# AT90CAN128 device description
Architecture: AVR8; Family: megaAVR
Registers are 8-bit, access not given, no defined reset value unless marked. A register's access mark holds for its fields unless they carry their own. Offsets are from the block's base; [hi:lo] are bit positions; {n}, {i} and the like mark numbered series.

## TC3 (TC16 module) — Timer/Counter, 16-bit
Instances: TC3 0x00
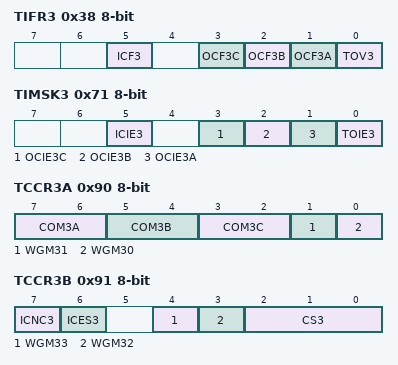
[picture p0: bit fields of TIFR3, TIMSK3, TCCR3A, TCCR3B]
0x38 TIFR3 — Timer/Counter Interrupt Flag register
  [5] ICF3 — Input Capture Flag 3
  [3] OCF3C — Output Compare Flag 3C
  [2] OCF3B — Output Compare Flag 3B
  [1] OCF3A — Output Compare Flag 3A
  [0] TOV3 — Timer/Counter3 Overflow Flag
0x71 TIMSK3 — Timer/Counter Interrupt Mask Register
  [5] ICIE3 — Timer/Counter3 Input Capture Interrupt Enable
  [3] OCIE3C — Timer/Counter3 Output CompareC Match Interrupt Enable
  [2] OCIE3B — Timer/Counter3 Output CompareB Match Interrupt Enable
  [1] OCIE3A — Timer/Counter3 Output CompareA Match Interrupt Enable
  [0] TOIE3 — Timer/Counter3 Overflow Interrupt Enable
0x90 TCCR3A — Timer/Counter3 Control Register A
  [7:6] COM3A — Compare Output Mode 3A, bits
  [5:4] COM3B — Compare Output Mode 3B, bits
  [3:2] COM3C — Compare Output Mode 3C, bits
  [1] WGM31 — Waveform Generation Mode
  [0] WGM30 — Waveform Generation Mode
0x91 TCCR3B — Timer/Counter3 Control Register B
  [7] ICNC3 — Input Capture 3 Noise Canceler
  [6] ICES3 — Input Capture 3 Edge Select
  [4] WGM33 (bit 2 of the value upward) — Waveform Generation Mode
  [3] WGM32 (bit 2 of the value upward) — Waveform Generation Mode
  [2:0] CS3 — Prescaler source of Timer/Counter 3
    0=No Clock Source (Stopped); 1=Running, No Prescaling; 2=Running, CLK/8; 3=Running, CLK/64; 4=Running, CLK/256; 5=Running, CLK/1024; 6=Running, ExtClk Tx Falling Edge; 7=Running, ExtClk Tx Rising Edge
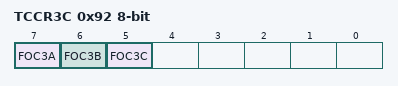
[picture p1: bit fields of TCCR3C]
0x92 TCCR3C — Timer/Counter 3 Control Register C
  [7] FOC3A — Force Output Compare 3A
  [6] FOC3B — Force Output Compare 3B
  [5] FOC3C — Force Output Compare 3C
0x94 TCNT3 16-bit — Timer/Counter3 Bytes
0x96 ICR3 16-bit — Timer/Counter3 Input Capture Register Bytes
0x98 OCR3A 16-bit — Timer/Counter3 Output Compare Register Bytes
0x9A OCR3B 16-bit — Timer/Counter3 Output Compare Register Bytes
0x9C OCR3C 16-bit — Timer/Counter3 Output Compare Register Bytes

## TC2 (TC8_ASYNC module) — Timer/Counter, 8-bit Async
Instances: TC2 0x00
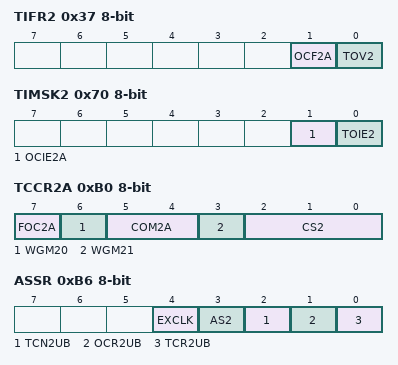
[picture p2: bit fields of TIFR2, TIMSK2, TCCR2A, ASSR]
0x37 TIFR2 — Timer/Counter Interrupt Flag Register
  [1] OCF2A — Output Compare Flag 2
  [0] TOV2 — Timer/Counter2 Overflow Flag
0x43 GTCCR — General Timer/Counter Control Register
  [1] PSR2 — Prescaler Reset Timer/Counter2
0x70 TIMSK2 — Timer/Counter Interrupt Mask register
  [1] OCIE2A — Timer/Counter2 Output Compare Match Interrupt Enable
  [0] TOIE2 — Timer/Counter2 Overflow Interrupt Enable
0xB0 TCCR2A — Timer/Counter2 Control Register
  [7] FOC2A — Force Output Compare
  [6] WGM20 — Waveform Genration Mode
    0=Normal; 2=PWM, Phase Correct; 1=CTC; 3=Fast PWM
  [5:4] COM2A — Compare Output Mode bits
  [3] WGM21 — Waveform Generation Mode
  [2:0] CS2 — Clock Select bits
    0=No Clock Source (Stopped); 1=Running, No Prescaling; 2=Running, CLK/8; 3=Running, CLK/32; 4=Running, CLK/64; 5=Running, CLK/128; 6=Running, CLK/256; 7=Running, CLK/1024
0xB2 TCNT2 — Timer/Counter2
0xB3 OCR2A — Timer/Counter2 Output Compare Register
0xB6 ASSR — Asynchronous Status Register
  [4] EXCLK — Enable External Clock Interrupt
  [3] AS2 — AS2: Asynchronous Timer/Counter2
  [2] TCN2UB — TCN2UB: Timer/Counter2 Update Busy
  [1] OCR2UB — Output Compare Register2 Update Busy
  [0] TCR2UB — TCR2UB: Timer/Counter Control Register2 Update Busy

## WDT — Watchdog Timer
Instances: WDT 0x00
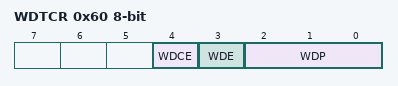
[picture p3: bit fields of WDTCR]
0x60 WDTCR — Watchdog Timer Control Register
  [4] WDCE — Watchdog Change Enable
  [3] WDE — Watch Dog Enable
  [2:0] WDP — Watch Dog Timer Prescaler bits
    0=Oscillator Cycles 16K; 1=Oscillator Cycles 32K; 2=Oscillator Cycles 64K; 3=Oscillator Cycles 128K; 4=Oscillator Cycles 256K; 5=Oscillator Cycles 512K; 6=Oscillator Cycles 1024K; 7=Oscillator Cycles 2048K

## ADC — Analog-to-Digital Converter
Instances: ADC 0x00
0x78 ADC 16-bit — ADC Data Register Bytes
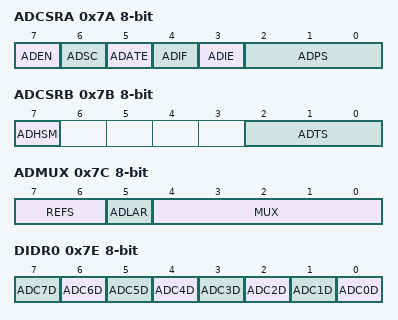
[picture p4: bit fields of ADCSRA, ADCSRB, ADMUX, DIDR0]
0x7A ADCSRA — The ADC Control and Status register
  [7] ADEN — ADC Enable
  [6] ADSC — ADC Start Conversion
  [5] ADATE — ADC Auto Trigger Enable
  [4] ADIF — ADC Interrupt Flag
  [3] ADIE — ADC Interrupt Enable
  [2:0] ADPS — ADC Prescaler Select Bits
    0=2; 1=2; 2=4; 3=8; 4=16; 5=32; 6=64; 7=128
0x7B ADCSRB — ADC Control and Status Register B
  [7] ADHSM — ADC High Speed Mode
  [2:0] ADTS — ADC Auto Trigger Sources
    0=Free Running mode; 1=Analog Comparator; 2=External Interrupt Request 0; 3=Timer/Counter0 Compare Match A; 4=Timer/Counter0 Overflow; 5=Timer/Counter1 Compare Match B; 6=Timer/Counter1 Overflow; 7=Timer/Counter1 Capture Event
0x7C ADMUX — The ADC multiplexer Selection Register
  [7:6] REFS — Reference Selection Bits
    0=AREF, Internal Vref turned off; 1=AVCC with external capacitor at AREF pin; 3=Internal 2.56V Voltage Reference with external capacitor at AREF pin
  [5] ADLAR — Left Adjust Result
  [4:0] MUX — Analog Channel and Gain Selection Bits
0x7E DIDR0 — Digital Input Disable Register 1
  [n] ADC{n}D (n=0..7) — ADC{n} Digital input Disable

## AC — Analog Comparator
Instances: AC 0x00
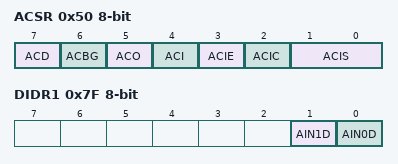
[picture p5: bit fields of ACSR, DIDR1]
0x50 ACSR — Analog Comparator Control And Status Register
  [7] ACD — Analog Comparator Disable
  [6] ACBG — Analog Comparator Bandgap Select
  [5] ACO — Analog Compare Output
  [4] ACI — Analog Comparator Interrupt Flag
  [3] ACIE — Analog Comparator Interrupt Enable
  [2] ACIC — Analog Comparator Input Capture Enable
  [1:0] ACIS — Analog Comparator Interrupt Mode Select bits
    0=Interrupt on Toggle; 2=Interrupt on Falling Edge; 3=Interrupt on Rising Edge
0x7B ADCSRB — ADC Control and Status Register B
  [6] ACME — Analog Comparator Multiplexer Enable
0x7F DIDR1
  [1] AIN1D — AIN1 Digital Input Disable
  [0] AIN0D — AIN0 Digital Input Disable
